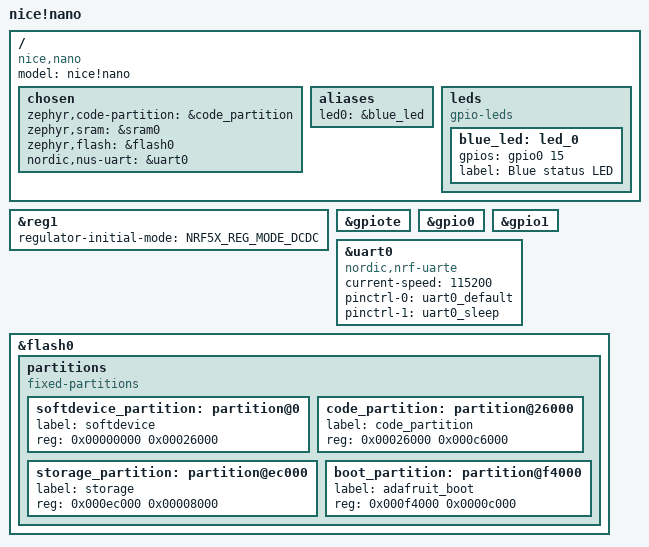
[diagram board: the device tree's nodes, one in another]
/*
 * nice!nano board definition based on the ZMK board support.
 * SPDX-License-Identifier: MIT
 */

/dts-v1/;

#include <nordic/nrf52840_qiaa.dtsi>
#include "nice_nano-pinctrl.dtsi"

/ {
	model = "nice!nano";
	compatible = "nice,nano";

	chosen {
		zephyr,code-partition = &code_partition;
		zephyr,sram = &sram0;
		zephyr,flash = &flash0;
		nordic,nus-uart = &uart0;
	};

	aliases {
		led0 = &blue_led;
	};

	leds {
		compatible = "gpio-leds";
		blue_led: led_0 {
			gpios = <&gpio0 15 GPIO_ACTIVE_HIGH>;
			label = "Blue status LED";
		};
	};
};

&reg1 {
	regulator-initial-mode = <NRF5X_REG_MODE_DCDC>;
};

&gpiote {
	status = "okay";
};

&gpio0 {
	status = "okay";
};

&gpio1 {
	status = "okay";
};

&uart0 {
	compatible = "nordic,nrf-uarte";
	current-speed = <115200>;
	status = "okay";
	pinctrl-0 = <&uart0_default>;
	pinctrl-1 = <&uart0_sleep>;
	pinctrl-names = "default", "sleep";
};

&flash0 {
	partitions {
		compatible = "fixed-partitions";
		#address-cells = <1>;
		#size-cells = <1>;

		softdevice_partition: partition@0 {
			label = "softdevice";
			reg = <0x00000000 0x00026000>;
		};

		code_partition: partition@26000 {
			label = "code_partition";
			reg = <0x00026000 0x000c6000>;
		};

		storage_partition: partition@ec000 {
			label = "storage";
			reg = <0x000ec000 0x00008000>;
		};

		boot_partition: partition@f4000 {
			label = "adafruit_boot";
			reg = <0x000f4000 0x0000c000>;
		};
	};
};

